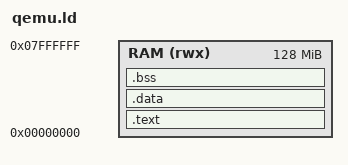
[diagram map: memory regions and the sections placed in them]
MEMORY
{
    RAM (rwx) : ORIGIN = 0x00000000, LENGTH = 0x08000000
}

SECTIONS
{
    .text :
    {
        _text = .;
        KEEP(*(.vectors))
        *(.text*)
        *(.rodata*)
        _etext = .;
    } > RAM

    .data : 
    {
        _data = .;
        *(vtable)
        *(.data*)
        _edata = .;
    } > RAM

    .bss :
    {
        _bss = .;
        *(.bss*)
        *(COMMON)
        _ebss = .;
    } > RAM
}
